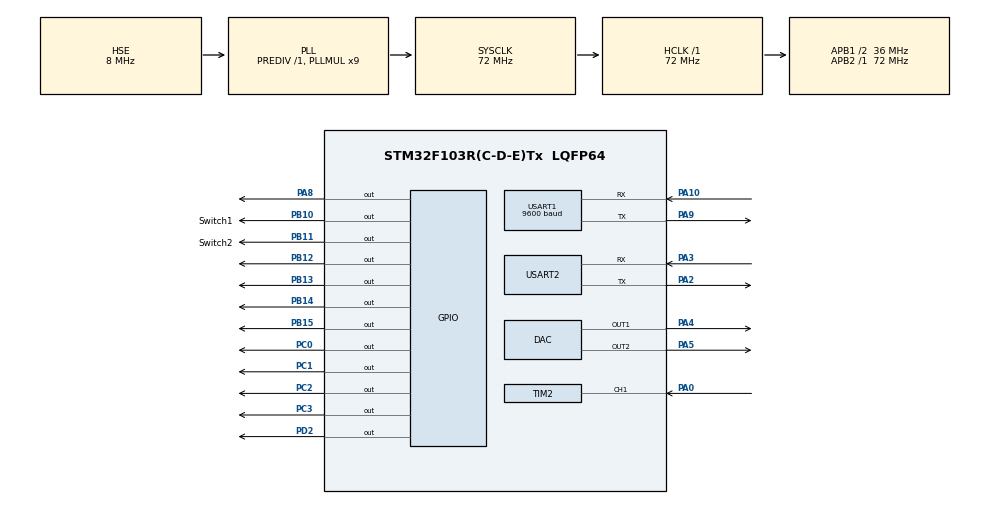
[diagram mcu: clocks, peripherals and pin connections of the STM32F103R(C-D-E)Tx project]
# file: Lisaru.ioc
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DAC.DAC_OutputBuffer=DAC_OUTPUTBUFFER_DISABLE
DAC.DAC_OutputBuffer2=DAC_OUTPUTBUFFER_DISABLE
DAC.DAC_Trigger=DAC_TRIGGER_T6_TRGO
DAC.DAC_Trigger2=DAC_TRIGGER_T7_TRGO
Dma.DAC_CH1.1.Direction=DMA_MEMORY_TO_PERIPH
Dma.DAC_CH1.1.Instance=DMA2_Channel3
Dma.DAC_CH1.1.MemDataAlignment=DMA_MDATAALIGN_HALFWORD
Dma.DAC_CH1.1.MemInc=DMA_MINC_ENABLE
Dma.DAC_CH1.1.Mode=DMA_CIRCULAR
Dma.DAC_CH1.1.PeriphDataAlignment=DMA_PDATAALIGN_HALFWORD
Dma.DAC_CH1.1.PeriphInc=DMA_PINC_DISABLE
Dma.DAC_CH1.1.Priority=DMA_PRIORITY_LOW
Dma.DAC_CH2.2.Direction=DMA_MEMORY_TO_PERIPH
Dma.DAC_CH2.2.Instance=DMA2_Channel4
Dma.DAC_CH2.2.MemDataAlignment=DMA_MDATAALIGN_HALFWORD
Dma.DAC_CH2.2.MemInc=DMA_MINC_ENABLE
Dma.DAC_CH2.2.Mode=DMA_CIRCULAR
Dma.DAC_CH2.2.PeriphDataAlignment=DMA_PDATAALIGN_HALFWORD
Dma.DAC_CH2.2.PeriphInc=DMA_PINC_DISABLE
Dma.DAC_CH2.2.Priority=DMA_PRIORITY_LOW
Dma.Request0=USART2_RX
Dma.Request1=DAC_CH1
Dma.Request2=DAC_CH2
Dma.USART2_RX.0.Direction=DMA_PERIPH_TO_MEMORY
Dma.USART2_RX.0.Instance=DMA1_Channel6
Dma.USART2_RX.0.MemDataAlignment=DMA_MDATAALIGN_BYTE
Dma.USART2_RX.0.MemInc=DMA_MINC_ENABLE
Dma.USART2_RX.0.Mode=DMA_CIRCULAR
Dma.USART2_RX.0.PeriphDataAlignment=DMA_PDATAALIGN_BYTE
Dma.USART2_RX.0.PeriphInc=DMA_PINC_DISABLE
Dma.USART2_RX.0.Priority=DMA_PRIORITY_LOW
Mcu.Family=STM32F1
Mcu.Name=STM32F103R(C-D-E)Tx
Mcu.Package=LQFP64
NVIC.DMA1_Channel6_IRQn=true\:0\:0\:false\:false\:true\:false\:true\:true
NVIC.PriorityGroup=NVIC_PRIORITYGROUP_4
NVIC.TIM3_IRQn=true\:0\:0\:false\:false\:true\:true\:true\:true
NVIC.TIM4_IRQn=true\:0\:0\:false\:false\:true\:true\:true\:true
NVIC.TIM6_IRQn=true\:1\:0\:true\:false\:true\:true\:true\:true
NVIC.TIM7_IRQn=true\:1\:0\:true\:false\:true\:true\:true\:true
NVIC.USART2_IRQn=true\:0\:0\:false\:false\:true\:true\:true\:true
PA0-WKUP.Signal=S_TIM2_CH1_ETR
PA10.Mode=Asynchronous
PA10.Signal=USART1_RX
PA13.Mode=Serial_Wire
PA13.Signal=SYS_JTMS-SWDIO
PA14.Mode=Serial_Wire
PA14.Signal=SYS_JTCK-SWCLK
PA2.Mode=Asynchronous
PA2.Signal=USART2_TX
PA3.Mode=Asynchronous
PA3.Signal=USART2_RX
PA4.Signal=COMP_DAC1_group
PA5.Signal=COMP_DAC2_group
PA8.Signal=GPIO_Output
PA9.Mode=Asynchronous
PA9.Signal=USART1_TX
PB10.GPIO_Label=Switch1
PB10.Signal=GPIO_Output
PB11.GPIO_Label=Switch2
PB11.Signal=GPIO_Output
PB12.Signal=GPIO_Output
PB13.Signal=GPIO_Output
PB14.Signal=GPIO_Output
PB15.Signal=GPIO_Output
PC0.Signal=GPIO_Output
PC1.Signal=GPIO_Output
PC2.Signal=GPIO_Output
PC3.Signal=GPIO_Output
PD0-OSC_IN.Mode=HSE-External-Oscillator
PD0-OSC_IN.Signal=RCC_OSC_IN
PD1-OSC_OUT.Mode=HSE-External-Oscillator
PD1-OSC_OUT.Signal=RCC_OSC_OUT
PD2.Signal=GPIO_Output
ProjectManager.HeapSize=0x200
ProjectManager.StackSize=0x400
ProjectManager.TargetToolchain=MDK-ARM V5.32
RCC.AHBFreq_Value=72000000
RCC.APB1CLKDivider=RCC_HCLK_DIV2
RCC.APB1Freq_Value=36000000
RCC.APB1TimFreq_Value=72000000
RCC.APB2Freq_Value=72000000
RCC.APB2TimFreq_Value=72000000
RCC.HCLKFreq_Value=72000000
RCC.PLLMUL=RCC_PLL_MUL9
RCC.PLLSourceVirtual=RCC_PLLSOURCE_HSE
RCC.SYSCLKFreq_VALUE=72000000
RCC.SYSCLKSource=RCC_SYSCLKSOURCE_PLLCLK
RCC.USBFreq_Value=72000000
SH.COMP_DAC1_group.0=DAC_OUT1,DAC_OUT1
SH.COMP_DAC2_group.0=DAC_OUT2,DAC_OUT2
SH.S_TIM2_CH1_ETR.0=TIM2_CH1,TriggerSource_TI1FP1
TIM3.Period=100
TIM3.Prescaler=71
TIM4.Period=9999
TIM4.Prescaler=7199
TIM6.AutoReloadPreload=TIM_AUTORELOAD_PRELOAD_ENABLE
TIM6.Period=100
TIM6.Prescaler=71
TIM6.TIM_MasterOutputTrigger=TIM_TRGO_UPDATE
TIM7.AutoReloadPreload=TIM_AUTORELOAD_PRELOAD_ENABLE
TIM7.Period=100
TIM7.Prescaler=71
TIM7.TIM_MasterOutputTrigger=TIM_TRGO_UPDATE
USART1.BaudRate=9600
USART1.VirtualMode=VM_ASYNC
USART2.VirtualMode=VM_ASYNC
VP_TIM2_VS_ControllerModeClock.Mode=Clock Mode
VP_TIM3_VS_ClockSourceINT.Mode=Internal
VP_TIM4_VS_ClockSourceINT.Mode=Internal
VP_TIM6_VS_ClockSourceINT.Mode=Enable_Timer
VP_TIM7_VS_ClockSourceINT.Mode=Enable_Timer
board=custom

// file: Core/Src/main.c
/* USER CODE BEGIN Header */
/**
  ******************************************************************************
  * @file           : main.c
  * @brief          : Main program body
  ******************************************************************************
  * @attention
  *
  * Copyright (c) 2022 STMicroelectronics.
  * All rights reserved.
  *
  * This software is licensed under terms that can be found in the LICENSE file
  * in the root directory of this software component.
  * If no LICENSE file comes with this software, it is provided AS-IS.
  *
  ******************************************************************************
  */
/* USER CODE END Header */
#include "main.h"
#include "dac.h"
#include "dma.h"
#include "tim.h"
#include "usart.h"
#include "gpio.h"

/* USER CODE BEGIN Includes */
#include "bsp_user.h"
/* USER CODE END Includes */

void SystemClock_Config(void);

int main(void)
{

  /* MCU Configuration--------------------------------------------------------*/

  /* Reset of all peripherals, Initializes the Flash interface and the Systick. */
  HAL_Init();

  /* Configure the system clock */
  SystemClock_Config();

  /* Initialize all configured peripherals */
  MX_GPIO_Init();
  MX_DMA_Init();
  MX_USART1_UART_Init();
  MX_USART2_UART_Init();
  MX_TIM2_Init();
  MX_TIM4_Init();
  MX_DAC_Init();
  MX_TIM7_Init();
  MX_TIM6_Init();
  MX_TIM3_Init();
  /* USER CODE B
EGIN 2 */
	bsp_Init();
  /* USER CODE END 2 */

  /* Infinite loop */
  /* USER CODE BEGIN WHILE */
  while (1)
  {
		bsp_imag_select();
    /* USER CODE END WHILE */

  }
}

void SystemClock_Config(void)
{
  RCC_OscInitTypeDef RCC_OscInitStruct = {0};
  RCC_ClkInitTypeDef RCC_ClkInitStruct = {0};

  /** Initializes the RCC Oscillators according to the specified parameters
  * in the RCC_OscInitTypeDef structure.
  */
  RCC_OscInitStruct.OscillatorType = RCC_OSCILLATORTYPE_HSE;
  RCC_OscInitStruct.HSEState = RCC_HSE_ON;
  RCC_OscInitStruct.HSEPredivValue = RCC_HSE_PREDIV_DIV1;
  RCC_OscInitStruct.HSIState = RCC_HSI_ON;
  RCC_OscInitStruct.PLL.PLLState = RCC_PLL_ON;
  RCC_OscInitStruct.PLL.PLLSource = RCC_PLLSOURCE_HSE;
  RCC_OscInitStruct.PLL.PLLMUL = RCC_PLL_MUL9;
  if (HAL_RCC_OscConfig(&RCC_OscInitStruct) != HAL_OK)
  {
    Error_Handler();
  }

  /** Initializes the CPU, AHB and APB buses clocks
  */
  RCC_ClkInitStruct.ClockType = RCC_CLOCKTYPE_HCLK|RCC_CLOCKTYPE_SYSCLK
                              |RCC_CLOCKTYPE_PCLK1|RCC_CLOCKTYPE_PCLK2;
  RCC_ClkInitStruct.SYSCLKSource = RCC_SYSCLKSOURCE_PLLCLK;
  RCC_ClkInitStruct.AHBCLKDivider = RCC_SYSCLK_DIV1;
  RCC_ClkInitStruct.APB1CLKDivider = RCC_HCLK_DIV2;
  RCC_ClkInitStruct.APB2CLKDivider = RCC_HCLK_DIV1;

  if (HAL_RCC_ClockConfig(&RCC_ClkInitStruct, FLASH_LATENCY_2) != HAL_OK)
  {
    Error_Handler();
  }
}

void Error_Handler(void)
{
  __disable_irq();
  while (1)
  {
  }
}
